# STM32F7x2_v1r0 register map
File version: 1.0
Registers are 32-bit, read-write, reset 0x0 unless marked. A register's access mark holds for its fields unless they carry their own. Offsets are from the block's base; [hi:lo] are bit positions.

## TIM13 — General-purpose-timers
Base 0x40001C00
Same registers: TIM14 0x40002000, TIM10 0x40014400, TIM11 0x40014800
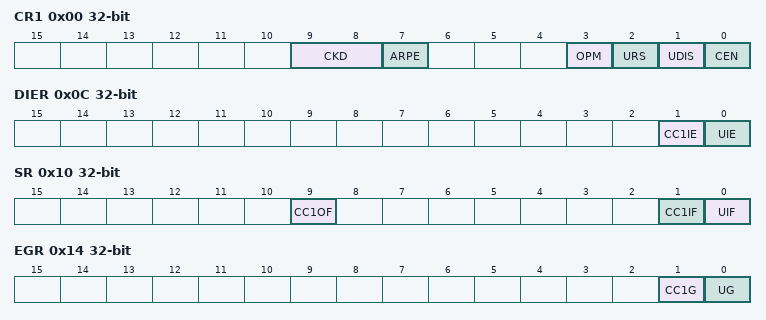
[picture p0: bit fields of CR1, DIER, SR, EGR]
0x00 CR1 — control register 1
  [9:8] CKD — Clock division
  [7] ARPE — Auto-reload preload enable
  [3] OPM — One-pulse mode
  [2] URS — Update request source
  [1] UDIS — Update disable
  [0] CEN — Counter enable
0x08 SMCR ro — slave mode control register
  [31:0] Res
0x0C DIER — DMA/Interrupt enable register
  [1] CC1IE — Capture/Compare 1 interrupt enable
  [0] UIE — Update interrupt enable
0x10 SR — status register
  [9] CC1OF — Capture/Compare 1 overcapture flag
  [1] CC1IF — Capture/compare 1 interrupt flag
  [0] UIF — Update interrupt flag
0x14 EGR wo — event generation register
  [1] CC1G — Capture/compare 1 generation
  [0] UG — Update generation
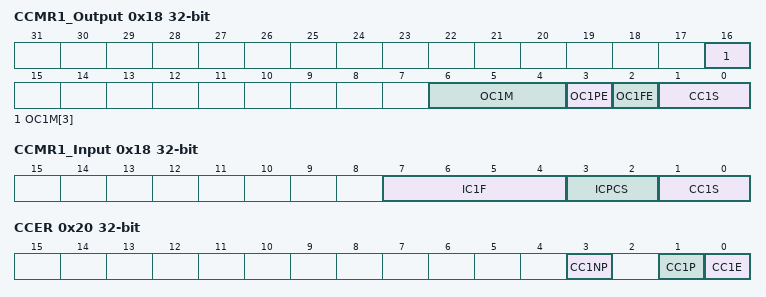
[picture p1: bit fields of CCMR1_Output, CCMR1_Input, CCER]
0x18 CCMR1_Output — capture/compare mode register 1 (output mode)
  [16] OC1M[3] — Output Compare 1 mode - bit 3
  [6:4] OC1M — Output Compare 1 mode
  [3] OC1PE — Output Compare 1 preload enable
  [2] OC1FE — Output Compare 1 fast enable
  [1:0] CC1S — Capture/Compare 1 selection
0x18 CCMR1_Input (alternate view of CCMR1_Output) — capture/compare mode register 1 (input mode)
  [7:4] IC1F — Input capture 1 filter
  [3:2] ICPCS — Input capture 1 prescaler
  [1:0] CC1S — Capture/Compare 1 selection
0x20 CCER — capture/compare enable register
  [3] CC1NP — Capture/Compare 1 output Polarity
  [1] CC1P — Capture/Compare 1 output Polarity
  [0] CC1E — Capture/Compare 1 output enable
0x24 CNT — counter
  [15:0] CNT — counter value
0x28 PSC — prescaler
  [15:0] PSC — Prescaler value
0x2C ARR — auto-reload register
  [15:0] ARR — Auto-reload value
0x34 CCR1 — capture/compare register 1
  [15:0] CCR1 — Capture/Compare 1 value
0x50 OR — option register
  [1:0] TI1_RMP — TIM11 Input 1 remapping capability

## IWDG — Independent watchdog
Base 0x40003000
0x00 KR wo — Key register
  [15:0] KEY — Key value (write only, read 0000h)
0x04 PR — Prescaler register
  [2:0] PR — Prescaler divider
0x08 RLR reset 0xFFF — Reload register
  [11:0] RL — Watchdog counter reload value
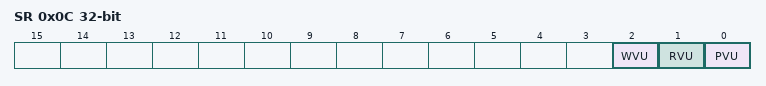
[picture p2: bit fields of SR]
0x0C SR ro — Status register
  [2] WVU — Watchdog counter window value update
  [1] RVU — Watchdog counter reload value update
  [0] PVU — Watchdog prescaler value update
0x10 WINR — Window register
  [11:0] WIN — Watchdog counter window value

## I2C1 — Inter-integrated circuit
Base 0x40005400
Same registers: I2C2 0x40005800, I2C3 0x40005C00
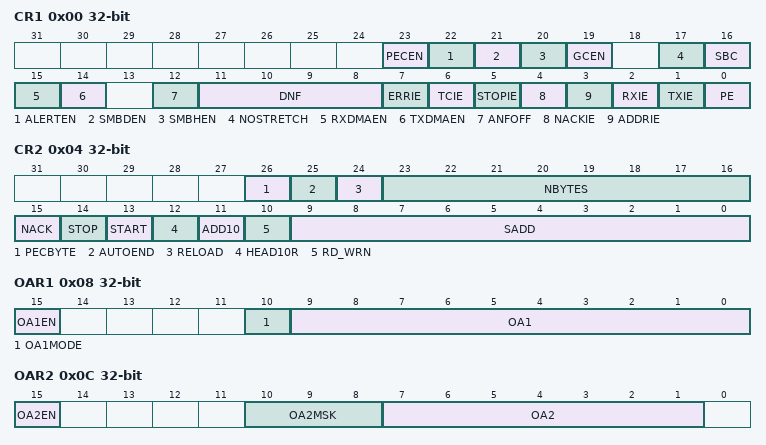
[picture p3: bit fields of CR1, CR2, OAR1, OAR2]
0x00 CR1 — Control register 1
  [23] PECEN — PEC enable
  [22] ALERTEN — SMBUS alert enable
  [21] SMBDEN — SMBus Device Default address enable
  [20] SMBHEN — SMBus Host address enable
  [19] GCEN — General call enable
  [17] NOSTRETCH — Clock stretching disable
  [16] SBC — Slave byte control
  [15] RXDMAEN — DMA reception requests enable
  [14] TXDMAEN — DMA transmission requests enable
  [12] ANFOFF — Analog noise filter OFF
  [11:8] DNF — Digital noise filter
  [7] ERRIE — Error interrupts enable
  [6] TCIE — Transfer Complete interrupt enable
  [5] STOPIE — STOP detection Interrupt enable
  [4] NACKIE — Not acknowledge received interrupt enable
  [3] ADDRIE — Address match interrupt enable (slave only)
  [2] RXIE — RX Interrupt enable
  [1] TXIE — TX Interrupt enable
  [0] PE — Peripheral enable
0x04 CR2 — Control register 2
  [26] PECBYTE — Packet error checking byte
  [25] AUTOEND — Automatic end mode (master mode)
  [24] RELOAD — NBYTES reload mode
  [23:16] NBYTES — Number of bytes
  [15] NACK — NACK generation (slave mode)
  [14] STOP — Stop generation (master mode)
  [13] START — Start generation
  [12] HEAD10R — 10-bit address header only read direction (master receiver mode)
  [11] ADD10 — 10-bit addressing mode (master mode)
  [10] RD_WRN — Transfer direction (master mode)
  [9:0] SADD — Slave address bit (master mode)
0x08 OAR1 — Own address register 1
  [15] OA1EN — Own Address 1 enable
  [10] OA1MODE — Own Address 1 10-bit mode
  [9:0] OA1 — Interface address
0x0C OAR2 — Own address register 2
  [15] OA2EN — Own Address 2 enable
  [10:8] OA2MSK — Own Address 2 masks
  [7:1] OA2 — Interface address
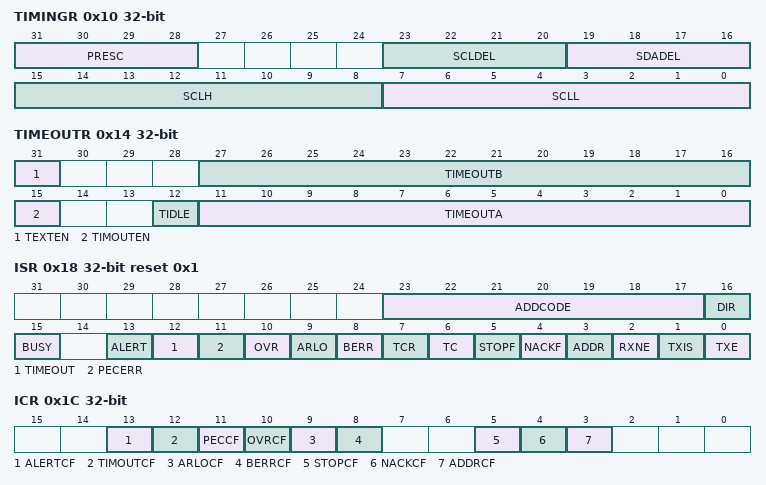
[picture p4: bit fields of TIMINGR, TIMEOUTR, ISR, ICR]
0x10 TIMINGR — Timing register
  [31:28] PRESC — Timing prescaler
  [23:20] SCLDEL — Data setup time
  [19:16] SDADEL — Data hold time
  [15:8] SCLH — SCL high period (master mode)
  [7:0] SCLL — SCL low period (master mode)
0x14 TIMEOUTR — Status register 1
  [31] TEXTEN — Extended clock timeout enable
  [27:16] TIMEOUTB — Bus timeout B
  [15] TIMOUTEN — Clock timeout enable
  [12] TIDLE — Idle clock timeout detection
  [11:0] TIMEOUTA — Bus timeout A
0x18 ISR access per field reset 0x1 — Interrupt and Status register
  [23:17] ADDCODE ro — Address match code (Slave mode)
  [16] DIR ro — Transfer direction (Slave mode)
  [15] BUSY ro — Bus busy
  [13] ALERT ro — SMBus alert
  [12] TIMEOUT ro — Timeout or t_low detection flag
  [11] PECERR ro — PEC Error in reception
  [10] OVR ro — Overrun/Underrun (slave mode)
  [9] ARLO ro — Arbitration lost
  [8] BERR ro — Bus error
  [7] TCR ro — Transfer Complete Reload
  [6] TC ro — Transfer Complete (master mode)
  [5] STOPF ro — Stop detection flag
  [4] NACKF ro — Not acknowledge received flag
  [3] ADDR ro — Address matched (slave mode)
  [2] RXNE ro — Receive data register not empty (receivers)
  [1] TXIS rw — Transmit interrupt status (transmitters)
  [0] TXE rw — Transmit data register empty (transmitters)
0x1C ICR wo — Interrupt clear register
  [13] ALERTCF — Alert flag clear
  [12] TIMOUTCF — Timeout detection flag clear
  [11] PECCF — PEC Error flag clear
  [10] OVRCF — Overrun/Underrun flag clear
  [9] ARLOCF — Arbitration lost flag clear
  [8] BERRCF — Bus error flag clear
  [5] STOPCF — Stop detection flag clear
  [4] NACKCF — Not Acknowledge flag clear
  [3] ADDRCF — Address Matched flag clear
0x20 PECR ro — PEC register
  [7:0] PEC — Packet error checking register
0x24 RXDR ro — Receive data register
  [7:0] RXDATA — 8-bit receive data
0x28 TXDR — Transmit data register
  [7:0] TXDATA — 8-bit transmit data
